# A8107M register map
Vendor: Amiccom Electronics Co., Ltd.; Series: A8107M; File version: 1.0
CPU: CM0 r0p0, little endian, no MPU, no FPU, 2 interrupt priority bits
Registers are 32-bit, read-write, reset 0x0 unless marked. A register's access mark holds for its fields unless they carry their own. Offsets are from the block's base; [hi:lo] are bit positions.

## I2CM — I2C Master
Base 0x40003000
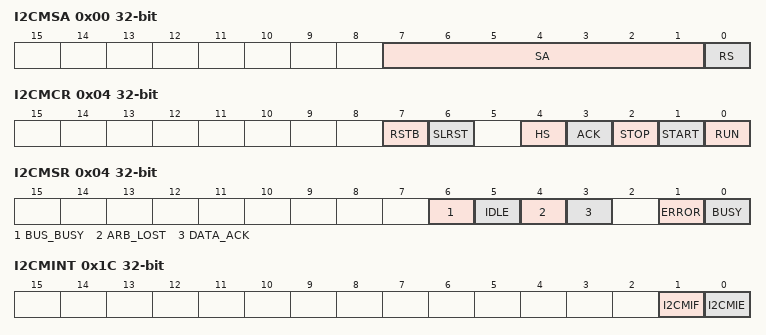
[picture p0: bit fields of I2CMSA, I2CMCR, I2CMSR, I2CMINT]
0x00 I2CMSA — I2C Master Slave address
  [7:1] SA — Slave Address
  [0] RS — Receive or Send in START condition. This bit work with START, RUN or HS, RUN.
    0=Transmitter; 1=Receiver
0x04 I2CMCR wo — I2C Master Control Register
  [7] RSTB — Reset Bit for I2C Master
    0=No effect; 1=Reset I2C controller
  [6] SLRST — Slave Reset
    0=No effect; 1=Reset slaves connected to I2C bus by generating 9 I2C_SCK clocks followed by STOP. This bit need with RUN to work.
  [4] HS — Transmission speed switch to High-speed.
    0=No effect; 1=Send START follow by Slave Address and Switching to High-speed
  [3] ACK — Master in Receive mode need set this bit. This bit must work with RUN bit.
    0=Read data follow by NAK; 1=Read data follow by ACK
  [2] STOP — Send STOP and return to Idle mode, and transmission speed switch to Standard.
    0=No effect; 1=Send STOP
  [1] START — Send START follow by Slave Address and SEND or RECEIVE. This bit need with RUN and RS to work.
    0=No effect; 1=Send START follow by Slave Address and SEND or RECEIVE
  [0] RUN — This bit work with START, STOP, ACK and HS.
    0=No effect; 1=Run a transmission
0x04 I2CMSR ro (alternate view of I2CMCR) — I2C Master Slave Register
  [6] BUS_BUSY — This bit is set by START conditions and reset by STOP conditions
    0=Bus not busy; 1=Bus is busy
  [5] IDLE — I2C Bus controller is in the idle state
    0=I2C Bus controller is not in idle state; 1=I2C Bus controller is in idle state
  [4] ARB_LOST — Due the last operation I2C Bus controller lost the arbitration
    0=not arbitration lost; 1=has arbitration lost
  [3] DATA_ACK — The acknowledged of DATA
    0=DATA with NAK; 1=DATA with ACK
  [1] ERROR — Due the last operation an error occurred, that include slave address wasn't acknowledged, transmitted data wasn't acknowledged, or I2C Bus controller lost the arbitration.
    0=Normal; 1=Some error occurred
  [0] BUSY — I2C Master is receiving, or transmitting data on the bus and other bits of I2CMSR are no valid.
    0=I2C Master controller not busy; 1=I2C Master controller is busy
0x08 I2CMBUF — I2C Master transmitted data Buffer
  [7:0] D — I2C Master write SEND data or read RECEIVE data
0x0C I2CMTP — I2C Master Timer Period
  [6:0] MTP — I2C master timer period register. The range of MTP[6:0] is 1~63
0x10 SCL_LP — I2C_SCL Low Period
  [3:0] SCL_LP — I2C master SCL low time period register. The range of SCL_LP[3:0] is 1~14.
0x14 SCL_HP — I2C_SCL High Period
  [3:0] SCL_HP — I2C master SCL high time period register. The range of SCL_HP[3:0] is 2~15.
0x18 SDA_SETUP — I2C_DAT Setup Period
  [3:0] SDA_SETUP — I2C Master SDA setup time register. The range of SDA_SETUP[3:0] is 2~15.
0x1C I2CMINT — I2C Master Interrupt
  [1] I2CMIF — I2C MASTER MODULE interrupt flag
    0=No effect; 1=I2C Master Interrupt occured. Write 1 to clean this bit.
  [0] I2CMIE — I2C Master interrupt enable
    0=Disable; 1=Enable
0x20 I2CBSEL — I2C Bus Select
  [0] I2CBSEL — I2C Bus select
    0=I2C_SCL connect to P0_04 and I2C_SCL connect to P0_05; 1=I2C_SCL connect to P0_10 and I2C_SCL connect to P0_11

## I2CS — I2C Slave
Base 0x40003800
0x00 I2CSOA — I2C Slave Own Address
  [6:0] ADDR — Slave device 7bits own address
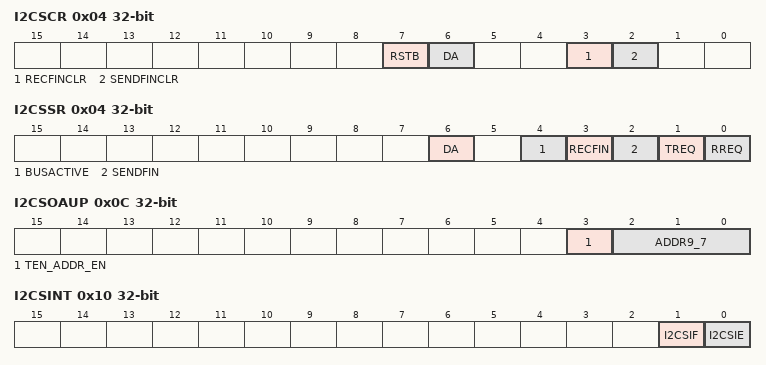
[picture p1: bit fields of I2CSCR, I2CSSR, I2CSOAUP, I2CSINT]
0x04 I2CSCR wo — I2C Slave Control Register
  [7] RSTB — I2C Slave controller reset
    0=No effect; 1=Reset I2C Slave controller
  [6] DA — I2C module Device Active
    0=I2C Slave device inactive; 1=I2C Slave device active
  [3] RECFINCLR — RECFIN clear
    0=No effect; 1=Clear RECFIN flag
  [2] SENDFINCLR — Clear SENDFIN flag
    0=No effect; 1=Clear SENDFIN flag
0x04 I2CSSR ro (alternate view of I2CSCR) — I2C Slave Status Register
  [6] DA — I2C slave Device Active
    0=I2C slave device inactive; 1=I2C slave device active
  [4] BUSACTIVE
    0=Bus no any transmission; 1=Bus has any transmission
  [3] RECFIN — Receive Finish
    0=No effect; 1=I2C Slave device receive finish. User need write 1 to RECFINCLR to clear this bit.
  [2] SENDFIN — Send Finish
    0=No effect; 1=I2C Slave device send finish. User need write 1 to SENDFINCLR to clear this bit.
  [1] TREQ — Transmit Request
    0=No transmit request; 1=I2C Slave device is addressed as transmitter and requires data from host. User need write data to I2CBUF to clear this bit.
  [0] RREQ — Receive Request
    0=No receive request; 1=Receive request occurred. User need read data from I2CSBUF to clear this bit.
0x08 I2CSBUF — I2C Slave Transmitted data Buffer
  [7:0] D — I2C Slave read data from D[7:0] when RREQ occurred, and write data to D[7:0] when TREQ occurred.
0x0C I2CSOAUP — I2C Salve Own Address UP
  [3] TEN_ADDR_EN — Ten bits address enable
    0=I2C Slave device using 7bits address; 1=I2C Slave device using 10bits address
  [2:0] ADDR9_7 — The higher 3 bits for I2C Slave device 10bits own address.
0x10 I2CSINT — I2C Slave Interrupt register
  [1] I2CSIF — I2C Slave device interrupt flag
    0=No effect; 1=I2C Slave device interrupt occurred. Write 1 to clear this bit
  [0] I2CSIE — I2C Slave device interrupt enable
    0=Disable; 1=Enable
